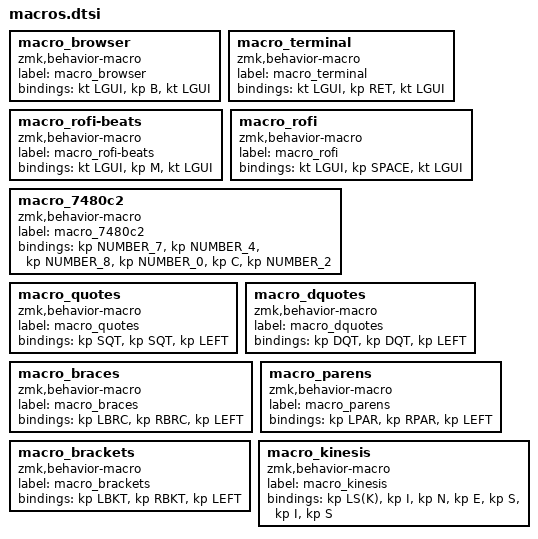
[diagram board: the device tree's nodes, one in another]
macro_browser: macro_browser{
compatible = "zmk,behavior-macro";
label = "macro_browser";
#binding-cells = <0>;
bindings = <&kt LGUI>, <&kp B>, <&kt LGUI>;
};
macro_terminal: macro_terminal{
compatible = "zmk,behavior-macro";
label = "macro_terminal";
#binding-cells = <0>;
bindings = <&kt LGUI>, <&kp RET>, <&kt LGUI>;
};
macro_rofi-beats: macro_rofi-beats{
compatible = "zmk,behavior-macro";
label = "macro_rofi-beats";
#binding-cells = <0>;
bindings = <&kt LGUI>, <&kp M>, <&kt LGUI>;
};
macro_rofi: macro_rofi{
compatible = "zmk,behavior-macro";
label = "macro_rofi";
#binding-cells = <0>;
bindings = <&kt LGUI>, <&kp SPACE>, <&kt LGUI>;
};
macro_7480c2: macro_7480c2{
compatible = "zmk,behavior-macro";
label = "macro_7480c2";
#binding-cells = <0>;
bindings = <&kp NUMBER_7>, <&kp NUMBER_4>, <&kp NUMBER_8>, <&kp NUMBER_0>, <&kp C>, <&kp NUMBER_2>;
};
macro_quotes: macro_quotes{
compatible = "zmk,behavior-macro";
label = "macro_quotes";
#binding-cells = <0>;
bindings = <&kp SQT>, <&kp SQT>, <&kp LEFT>;
};
macro_dquotes: macro_dquotes{
compatible = "zmk,behavior-macro";
label = "macro_dquotes";
#binding-cells = <0>;
bindings = <&kp DQT>, <&kp DQT>, <&kp LEFT>;
};
macro_braces: macro_braces{
compatible = "zmk,behavior-macro";
label = "macro_braces";
#binding-cells = <0>;
bindings = <&kp LBRC>, <&kp RBRC>, <&kp LEFT>;
};
macro_parens: macro_parens{
compatible = "zmk,behavior-macro";
label = "macro_parens";
#binding-cells = <0>;
bindings = <&kp LPAR>, <&kp RPAR>, <&kp LEFT>;
};
macro_brackets: macro_brackets{
compatible = "zmk,behavior-macro";
label = "macro_brackets";
#binding-cells = <0>;
bindings = <&kp LBKT>, <&kp RBKT>, <&kp LEFT>;
};
macro_kinesis: macro_kinesis{
compatible = "zmk,behavior-macro";
label = "macro_kinesis";
#binding-cells = <0>;
bindings = <&kp LS(K)>, <&kp I>, <&kp N>, <&kp E>, <&kp S>, <&kp I>, <&kp S>;
};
